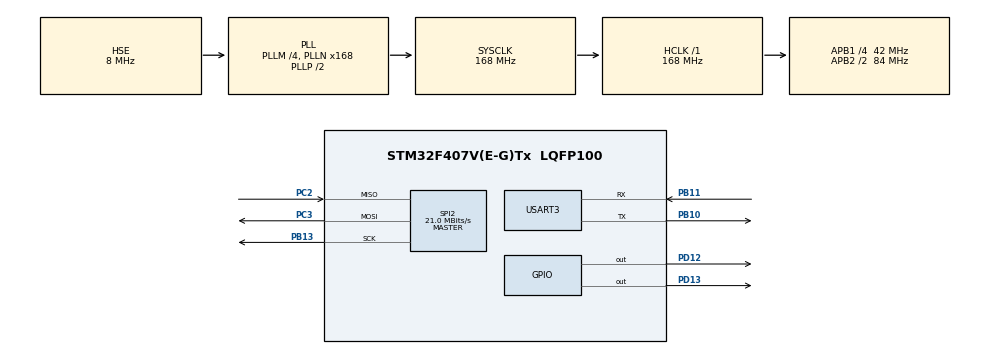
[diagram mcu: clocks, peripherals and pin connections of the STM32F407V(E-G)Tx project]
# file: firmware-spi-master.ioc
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Mcu.Family=STM32F4
Mcu.Name=STM32F407V(E-G)Tx
Mcu.Package=LQFP100
NVIC.PriorityGroup=NVIC_PRIORITYGROUP_4
PB10.Mode=Asynchronous
PB10.Signal=USART3_TX
PB11.Mode=Asynchronous
PB11.Signal=USART3_RX
PB13.Mode=Full_Duplex_Master
PB13.Signal=SPI2_SCK
PB9.Signal=SPI2_NSS
PC2.Mode=Full_Duplex_Master
PC2.Signal=SPI2_MISO
PC3.Mode=Full_Duplex_Master
PC3.Signal=SPI2_MOSI
PD12.Signal=GPIO_Output
PD13.Signal=GPIO_Output
PH0-OSC_IN.Mode=HSE-External-Oscillator
PH0-OSC_IN.Signal=RCC_OSC_IN
PH1-OSC_OUT.Mode=HSE-External-Oscillator
PH1-OSC_OUT.Signal=RCC_OSC_OUT
ProjectManager.HeapSize=0x200
ProjectManager.StackSize=0x400
ProjectManager.TargetToolchain=Makefile
RCC.48MHZClocksFreq_Value=84000000
RCC.AHBFreq_Value=168000000
RCC.APB1CLKDivider=RCC_HCLK_DIV4
RCC.APB1Freq_Value=42000000
RCC.APB1TimFreq_Value=84000000
RCC.APB2CLKDivider=RCC_HCLK_DIV2
RCC.APB2Freq_Value=84000000
RCC.APB2TimFreq_Value=168000000
RCC.CortexFreq_Value=168000000
RCC.HCLKFreq_Value=168000000
RCC.HSE_VALUE=8000000
RCC.HSI_VALUE=16000000
RCC.LSE_VALUE=32768
RCC.PLLM=4
RCC.PLLN=168
RCC.PLLSourceVirtual=RCC_PLLSOURCE_HSE
RCC.SYSCLKFreq_VALUE=168000000
RCC.SYSCLKSource=RCC_SYSCLKSOURCE_PLLCLK
RCC.VCOOutputFreq_Value=336000000
SPI2.BaudRatePrescaler=SPI_BAUDRATEPRESCALER_2
SPI2.CalculateBaudRate=21.0 MBits/s
SPI2.Direction=SPI_DIRECTION_2LINES
SPI2.Mode=SPI_MODE_MASTER
SPI2.VirtualType=VM_MASTER
USART3.VirtualMode=VM_ASYNC
board=custom

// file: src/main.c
/* USER CODE BEGIN Header */
/**
  ******************************************************************************
  * @file           : main.c
  * @brief          : Main program body
  ******************************************************************************
  * @attention
  *
  * <h2><center>&copy; Copyright (c) 2019 STMicroelectronics.
  * All rights reserved.</center></h2>
  *
  * This software component is licensed by ST under BSD 3-Clause license,
  * the "License"; You may not use this file except in compliance with the
  * License. You may obtain a copy of the License at:
  *                        opensource.org/licenses/BSD-3-Clause
  *
  ******************************************************************************
  */
/* USER CODE END Header */

#include "main.h"
#include <stdio.h>
#include <string.h>
#include "TCPServer.h"

/* USER CODE BEGIN Includes */
#define SSHigh() (GPIOB->ODR|=(1<<9))
#define SSLow() (GPIOB->ODR&=~(1<<9))
char temp_main[20];
/* USER CODE END Includes */

SPI_HandleTypeDef hspi2;

UART_HandleTypeDef huart3;

/* USER CODE BEGIN PV */
//uint8_t txd[20],rxd[20];
/* USER CODE END PV */

void SystemClock_Config(void);
static void MX_GPIO_Init(void);
static void MX_SPI2_Init(void);
static void MX_USART3_UART_Init(void);

void SPISend(char *txBuffer,char*rxBuffer,uint8_t len)
{

    SSLow();
  HAL_SPI_TransmitReceive(&hspi2,&txBuffer[0],&rxBuffer[0],len,10);
  SSHigh();
}

int main(void)
{
  /* USER CODE BEGIN 1 */
TCPServerInit(SPISend);
  /* USER CODE END 1 */

  /* MCU Configuration--------------------------------------------------------*/

  /* Reset of all peripherals, Initializes the Flash interface and the Systick. */
  HAL_Init();

  /* USER CODE BEGIN Init */
  //MX_GPIO_Init();
MX_SPI2_Init();
MX_USART3_UART_Init();
  MX_GPIO_Init();

  /* USER CODE END Init */

  /* Initialize all configured peripherals */
  /* USER CODE BEGIN 2 */
  //sprintf(txd,"%s","salam this is test");
  /* USER CODE END 2 */

  /* Infinite loop */
  while (1)
  {

  GPIOD->ODR^=1<<13;
  sprintf(temp_main,"NAME");
  SetSSID(temp_main);
  HAL_Delay(1000);
  sprintf(temp_main,"PASS");
  SetPassword(temp_main);
  HAL_Delay(1000);
  StartAp();
    HAL_Delay(1000);
    SendTCP("1234567890UV",12);
  //HAL_UART_Transmit(&huart3,rxd,20,10);
  HAL_Delay(1000);
//GPIOB->ODR^=1<<9;
  }
}

void SystemClock_Config(void)
{
  RCC_OscInitTypeDef RCC_OscInitStruct = {0};
  RCC_ClkInitTypeDef RCC_ClkInitStruct = {0};

  /** Configure the main internal regulator output voltage
  */
  __HAL_RCC_PWR_CLK_ENABLE();
  __HAL_PWR_VOLTAGESCALING_CONFIG(PWR_REGULATOR_VOLTAGE_SCALE1);
  /** Initializes the CPU, AHB and APB busses clocks
  */
  RCC_OscInitStruct.OscillatorType = RCC_OSCILLATORTYPE_HSE;
  RCC_OscInitStruct.HSEState = RCC_HSE_ON;
  RCC_OscInitStruct.PLL.PLLState = RCC_PLL_ON;
  RCC_OscInitStruct.PLL.PLLSource = RCC_PLLSOURCE_HSE;
  RCC_OscInitStruct.PLL.PLLM = 4;
  RCC_OscInitStruct.PLL.PLLN = 168;
  RCC_OscInitStruct.PLL.PLLP = RCC_PLLP_DIV2;
  RCC_OscInitStruct.PLL.PLLQ = 4;
  if (HAL_RCC_OscConfig(&RCC_OscInitStruct) != HAL_OK)
  {
    Error_Handler();
  }
  /** Initializes the CPU, AHB and APB busses clocks
  */
  RCC_ClkInitStruct.ClockType = RCC_CLOCKTYPE_HCLK|RCC_CLOCKTYPE_SYSCLK
                              |RCC_CLOCKTYPE_PCLK1|RCC_CLOCKTYPE_PCLK2;
  RCC_ClkInitStruct.SYSCLKSource = RCC_SYSCLKSOURCE_PLLCLK;
  RCC_ClkInitStruct.AHBCLKDivider = RCC_SYSCLK_DIV1;
  RCC_ClkInitStruct.APB1CLKDivider = RCC_HCLK_DIV4;
  RCC_ClkInitStruct.APB2CLKDivider = RCC_HCLK_DIV2;

  if (HAL_RCC_ClockConfig(&RCC_ClkInitStruct, FLASH_LATENCY_5) != HAL_OK)
  {
    Error_Handler();
  }
}

static void MX_SPI2_Init(void)
{

  /* SPI2 parameter configuration*/
  hspi2.Instance = SPI2;
  hspi2.Init.Mode = SPI_MODE_MASTER;
  hspi2.Init.Direction = SPI_DIRECTION_2LINES;
  hspi2.Init.DataSize = SPI_DATASIZE_8BIT;
  hspi2.Init.CLKPolarity = SPI_POLARITY_LOW;
  hspi2.Init.CLKPhase = SPI_PHASE_1EDGE;
  hspi2.Init.NSS = SPI_NSS_SOFT;
  hspi2.Init.BaudRatePrescaler = SPI_BAUDRATEPRESCALER_8;
  hspi2.Init.FirstBit = SPI_FIRSTBIT_MSB;
  hspi2.Init.TIMode = SPI_TIMODE_DISABLE;
  hspi2.Init.CRCCalculation = SPI_CRCCALCULATION_DISABLE;
  hspi2.Init.CRCPolynomial = 10;
  if (HAL_SPI_Init(&hspi2) != HAL_OK)
  {
    Error_Handler();
  }

}

static void MX_USART3_UART_Init(void)
{

  huart3.Instance = USART3;
  huart3.Init.BaudRate = 115200;
  huart3.Init.WordLength = UART_WORDLENGTH_8B;
  huart3.Init.StopBits = UART_STOPBITS_1;
  huart3.Init.Parity = UART_PARITY_NONE;
  huart3.Init.Mode = UART_MODE_TX_RX;
  huart3.Init.HwFlowCtl = UART_HWCONTROL_NONE;
  huart3.Init.OverSampling = UART_OVERSAMPLING_16;
  if (HAL_UART_Init(&huart3) != HAL_OK)
  {
    Error_Handler();
  }

}

static void MX_GPIO_Init(void)
{
  GPIO_InitTypeDef GPIO_InitStruct = {0};

  /* GPIO Ports Clock Enable */
  __HAL_RCC_GPIOH_CLK_ENABLE();
  __HAL_RCC_GPIOC_CLK_ENABLE();
  __HAL_RCC_GPIOB_CLK_ENABLE();
  __HAL_RCC_GPIOD_CLK_ENABLE();

  /*Configure GPIO pin Output Level */
  HAL_GPIO_WritePin(GPIOD, GPIO_PIN_12|GPIO_PIN_13, GPIO_PIN_RESET);

  /*Configure GPIO pins : PD12 PD13 */
  GPIO_InitStruct.Pin = GPIO_PIN_12|GPIO_PIN_13;
  GPIO_InitStruct.Mode = GPIO_MODE_OUTPUT_PP;
  GPIO_InitStruct.Pull = GPIO_NOPULL;
  GPIO_InitStruct.Speed = GPIO_SPEED_FREQ_LOW;
  HAL_GPIO_Init(GPIOD, &GPIO_InitStruct);
  GPIO_InitStruct.Pin = GPIO_PIN_9;
  GPIO_InitStruct.Mode = GPIO_MODE_OUTPUT_PP;
  GPIO_InitStruct.Pull = GPIO_NOPULL;
  GPIO_InitStruct.Speed = GPIO_SPEED_FREQ_VERY_HIGH;
  HAL_GPIO_Init(GPIOB, &GPIO_InitStruct);

}

void Error_Handler(void)
{
}

/************************ (C) COPYRIGHT STMicroelectronics *****END OF FILE****/
